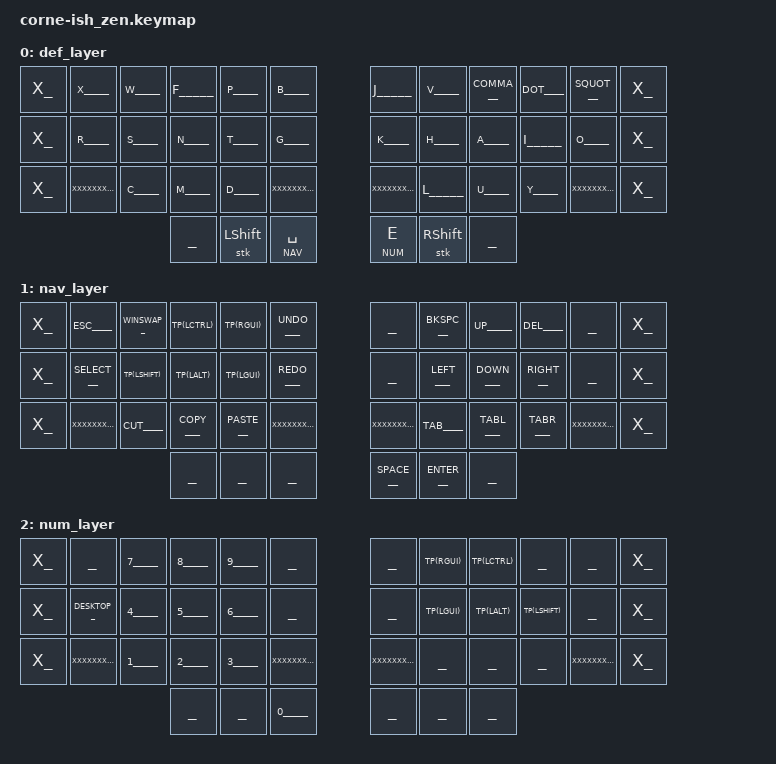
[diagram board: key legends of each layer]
#include <behaviors.dtsi>
#include <dt-bindings/zmk/keys.h>
#include <dt-bindings/zmk/bt.h>

#include "./helpers.h"
#include "./keycodes.h"

#define STICKY_KEY_TIMEOUT 60000

#define DEF 0
#define NAV 1
#define NUM 2
#define SYM 3
#define FUN 4

/**
 * Sticky key that does not time out rapidly
 * Useful for simulating one-shot shift 
 */
ZMK_BEHAVIOR(stk, sticky_key,
  quick-release;
  release-after-ms = <STICKY_KEY_TIMEOUT>;
  bindings = <&kp>;
)

/**
 * Sticky key on tap, normal key on hold
 * Useful for modifier-clicking without the modifier remaining active
 */
ZMK_BEHAVIOR(tp, hold_tap,
  tapping_term_ms = <200>;
  flavor = "tap-preferred";
  bindings = <&kp>, <&sk>;
)
#define TP(KEY) &tp KEY KEY 

/**
// ╭─────┬─────────────┬─────────────┬─────────────┬─────────────┬─────────────╮   ╭─────────────┬─────────────┬─────────────┬─────────────┬─────────────┬─────╮
     _X_   ___________   ___________   ___________   ___________   ___________       ___________   ___________   ___________   ___________   ___________   _X_
// ├─────┼─────────────┼─────────────┼─────────────┼─────────────┼─────────────┤   ├─────────────┼─────────────┼─────────────┼─────────────┼─────────────┼─────┤
     _X_   ___________   ___________   ___________   ___________   ___________       ___________   ___________   ___________   ___________   ___________   _X_
// ├─────┼─────────────┼─────────────┼─────────────┼─────────────┼─────────────┤   ├─────────────┼─────────────┼─────────────┼─────────────┼─────────────┼─────┤
     _X_   XXXXXXXXXXX   ___________   ___________   ___________   XXXXXXXXXXX       XXXXXXXXXXX   ___________   ___________   ___________   XXXXXXXXXXX   _X_
// ╰─────┴─────────────┴─────────────┴─────────────┼─────────────┼─────────────┤   ├─────────────┼─────────────┼─────────────┴─────────────┴─────────────┴─────╯
                                       ___________   ___________   ___________       ___________   ___________   ___________
//                                   ╰─────────────┴─────────────┴─────────────╯   ╰─────────────┴─────────────┴─────────────╯ 
 */


/**
 * This is a variant of AptX mak mod based on
 * https://github.com/Apsu/zmk-luna/blob/main/config/luna.keymap
 */
ZMK_LAYER(def_layer,
// ╭─────┬─────────────┬─────────────┬─────────────┬─────────────┬─────────────╮   ╭─────────────┬─────────────┬─────────────┬─────────────┬─────────────┬─────╮
     _X_   _____X_____   _____W_____   _____F_____   _____P_____   _____B_____       _____J_____   _____V_____   ___COMMA___   ____DOT____   ___SQUOT___   _X_
// ├─────┼─────────────┼─────────────┼─────────────┼─────────────┼─────────────┤   ├─────────────┼─────────────┼─────────────┼─────────────┼─────────────┼─────┤
     _X_   _____R_____   _____S_____   _____N_____   _____T_____   _____G_____       _____K_____   _____H_____    _____A_____   _____I_____   _____O_____   _X_
// ├─────┼─────────────┼─────────────┼─────────────┼─────────────┼─────────────┤   ├─────────────┼─────────────┼─────────────┼─────────────┼─────────────┼─────┤
     _X_   XXXXXXXXXXX   _____C_____   _____M_____   _____D_____   XXXXXXXXXXX       XXXXXXXXXXX   _____L_____   _____U_____   _____Y_____   XXXXXXXXXXX   _X_
// ╰─────┴─────────────┴─────────────┴─────────────┼─────────────┼─────────────┤   ├─────────────┼─────────────┼─────────────┴─────────────┴─────────────┴─────╯
                                       ___________   &stk LSHIFT   &lt NAV SPC       &lt NUM E     &stk RSHIFT   ___________
//                                   ╰─────────────┴─────────────┴─────────────╯   ╰─────────────┴─────────────┴─────────────╯
)

/**
 * 
 */
ZMK_LAYER(nav_layer,
// ╭─────┬─────────────┬─────────────┬─────────────┬─────────────┬─────────────╮   ╭─────────────┬─────────────┬─────────────┬─────────────┬─────────────┬─────╮
     _X_   ____ESC____   __WINSWAP__   TP(LCTRL)     TP(RGUI)      ___UNDO____       ___________   ___BKSPC___   ____UP_____   ____DEL____   ___________   _X_
// ├─────┼─────────────┼─────────────┼─────────────┼─────────────┼─────────────┤   ├─────────────┼─────────────┼─────────────┼─────────────┼─────────────┼─────┤
     _X_   __SELECT___   TP(LSHIFT)    TP(LALT)      TP(LGUI)      ___REDO____       ___________   ___LEFT____   ___DOWN____   ___RIGHT___   ___________   _X_
// ├─────┼─────────────┼─────────────┼─────────────┼─────────────┼─────────────┤   ├─────────────┼─────────────┼─────────────┼─────────────┼─────────────┼─────┤
     _X_   XXXXXXXXXXX   ____CUT____   ___COPY____   ___PASTE___   XXXXXXXXXXX       XXXXXXXXXXX   ____TAB____   ___TABL____   ___TABR____   XXXXXXXXXXX   _X_
// ╰─────┴─────────────┴─────────────┴─────────────┼─────────────┼─────────────┤   ├─────────────┼─────────────┼─────────────┴─────────────┴─────────────┴─────╯
                                       ___________   ___________   ___________       ___SPACE___   ___ENTER___   ___________
//                                   ╰─────────────┴─────────────┴─────────────╯   ╰─────────────┴─────────────┴─────────────╯
)

/**
 * 
 */
ZMK_LAYER(num_layer,
// ╭─────┬─────────────┬─────────────┬─────────────┬─────────────┬─────────────╮   ╭─────────────┬─────────────┬─────────────┬─────────────┬─────────────┬─────╮
     _X_   ___________   _____7_____   _____8_____   _____9_____   ___________       ___________   TP(RGUI)      TP(LCTRL)     ___________   ___________   _X_
// ├─────┼─────────────┼─────────────┼─────────────┼─────────────┼─────────────┤   ├─────────────┼─────────────┼─────────────┼─────────────┼─────────────┼─────┤
     _X_   __DESKTOP__   _____4_____   _____5_____   _____6_____   ___________       ___________   TP(LGUI)      TP(LALT)      TP(LSHIFT)    ___________   _X_
// ├─────┼─────────────┼─────────────┼─────────────┼─────────────┼─────────────┤   ├─────────────┼─────────────┼─────────────┼─────────────┼─────────────┼─────┤
     _X_   XXXXXXXXXXX   _____1_____   _____2_____   _____3_____   XXXXXXXXXXX       XXXXXXXXXXX   ___________   ___________   ___________   XXXXXXXXXXX   _X_
// ╰─────┴─────────────┴─────────────┴─────────────┼─────────────┼─────────────┤   ├─────────────┼─────────────┼─────────────┴─────────────┴─────────────┴─────╯
                                       ___________   ___________   _____0_____       ___________   ___________   ___________
//                                   ╰─────────────┴─────────────┴─────────────╯   ╰─────────────┴─────────────┴─────────────╯ 
)


/*                KEY POSITIONS

  ╭────────────────────────╮ ╭────────────────────────╮
  │  0   1   2   3   4   5 │ │  6   7   8   9  10  11 │
  │ 12  13  14  15  16  17 │ │ 18  19  20  21  22  23 │
  │ 24  25  26  27  28  29 │ │ 30  31  32  33  34  35 │
  ╰───────────╮ 36  37  38 │ │ 39  40  41 ╭───────────╯
              ╰────────────╯ ╰────────────╯
*/


ZMK_COMBO(caps_word, &caps_word, 37 40, DEF)
ZMK_COMBO(kp_q, &kp Q, 1 2, DEF)
ZMK_COMBO(kp_z, &kp Z, 2 3, DEF)

 


/**
 * Used for having a repeat key on a layer key
ZMK_BEHAVIOR(mr, hold_tap,
  tapping_term_ms = <200>;
  flavor = "tap-preferred";
  bindings = <&mo>, <&key_repeat>;
)
#define MR(LAYER) &mr LAYER 0
 */



